# STM32WL5x_CM0P register map
File version: 1.5
CPU: CM0 r0p1, little endian, MPU, no FPU, 4 interrupt priority bits
Registers are 32-bit, read-write, reset 0x0 unless marked. A register's access mark holds for its fields unless they carry their own. Offsets are from the block's base; [hi:lo] are bit positions; {n}, {i} and the like mark numbered series.

## DMAMUX — DMA request multiplexer
Base 0x40020800
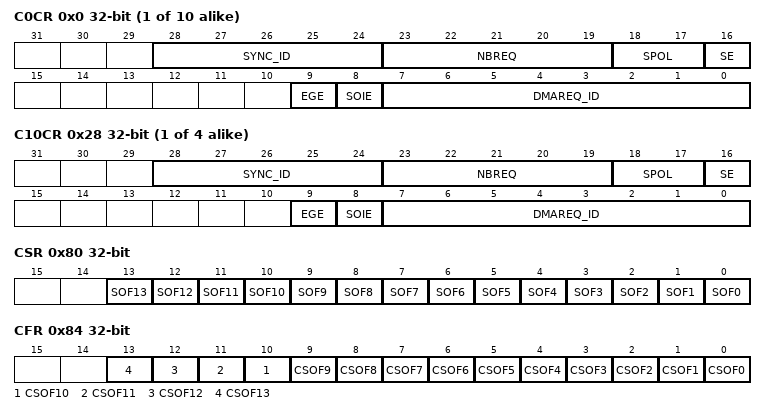
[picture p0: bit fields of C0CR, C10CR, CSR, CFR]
{0x0+4i} C{i}CR (i=0..9) — request line multiplexer channel x configuration register
  [28:24] SYNC_ID — Synchronization identification
  [23:19] NBREQ — Number of DMA requests minus 1 to forward
  [18:17] SPOL — Synchronization polarity
  [16] SE — Synchronization enable
  [9] EGE — Event generation enable
  [8] SOIE — Synchronization overrun interrupt enable
  [7:0] DMAREQ_ID — DMA request identification
{0x0+4i} C{i}CR (i=10..13)
  [28:24] SYNC_ID, [23:19] NBREQ, [18:17] SPOL, [16] SE, [9] EGE, [8] SOIE, [7:0] DMAREQ_ID
0x80 CSR ro — request line multiplexer interrupt channel status register
  [13] SOF13 — Synchronization overrun event flag
  [n] SOF{n} (n=0..12)
0x84 CFR — request line multiplexer interrupt channel clear flag register
  [n] CSOF{n} (n=0..13)
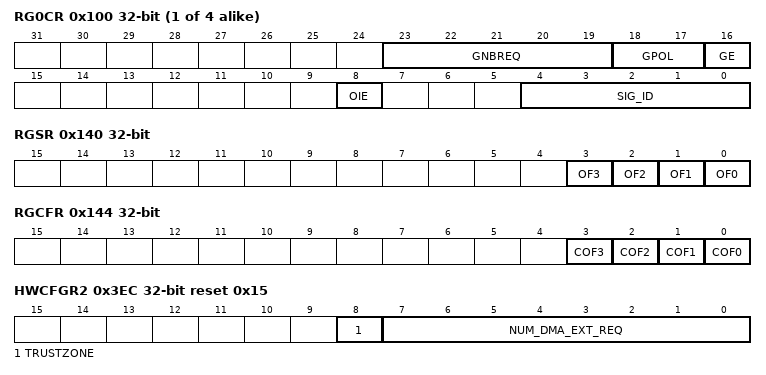
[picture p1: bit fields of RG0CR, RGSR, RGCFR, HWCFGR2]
{0x100+4i} RG{i}CR (i=0..3) — request generator channel x configuration register
  [23:19] GNBREQ — Number of DMA requests to be generated (minus 1)
  [18:17] GPOL — DMA request generator trigger polarity
  [16] GE — DMA request generator channel x enable
  [8] OIE — Trigger overrun interrupt enable
  [4:0] SIG_ID — Signal identification
0x140 RGSR ro — request generator interrupt status register
  [3] OF3 — Trigger overrun event flag
  [2] OF2
  [1] OF1
  [0] OF0
0x144 RGCFR wo — request generator interrupt clear flag register
  [3] COF3 — Clear trigger overrun event flag
  [2] COF2
  [1] COF1
  [0] COF0
0x3EC HWCFGR2 reset 0x15 — hardware configuration 2 register [non-user]
  [8] TRUSTZONE — TrustZone support
  [7:0] NUM_DMA_EXT_REQ — Number of DMA request trigger inputs
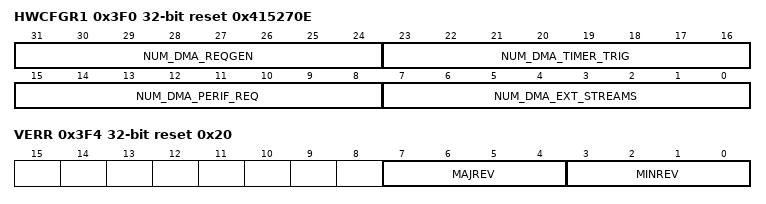
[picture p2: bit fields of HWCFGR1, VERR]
0x3F0 HWCFGR1 ro reset 0x415270E — hardware configuration 1 register [non-user]
  [31:24] NUM_DMA_REQGEN — number of DMA request generator channels
  [23:16] NUM_DMA_TIMER_TRIG — number of synchronization inputs
  [15:8] NUM_DMA_PERIF_REQ — number of DMA request lines from peripherals
  [7:0] NUM_DMA_EXT_STREAMS — number of DMA request line multiplexer (output) channels
0x3F4 VERR reset 0x20 — version register [non-user]
  [7:4] MAJREV — Major IP revision
  [3:0] MINREV — Minor IP revision
0x3F8 IPIDR ro reset 0x100011 — IP identification register [non-user]
  [31:0] ID — IP identification
0x3FC SIDR ro reset 0xA3C5DD01 — size identification register [non-user]
  [31:0] SID — Size identification

## PKA — Public key accelerator
Base 0x58002000
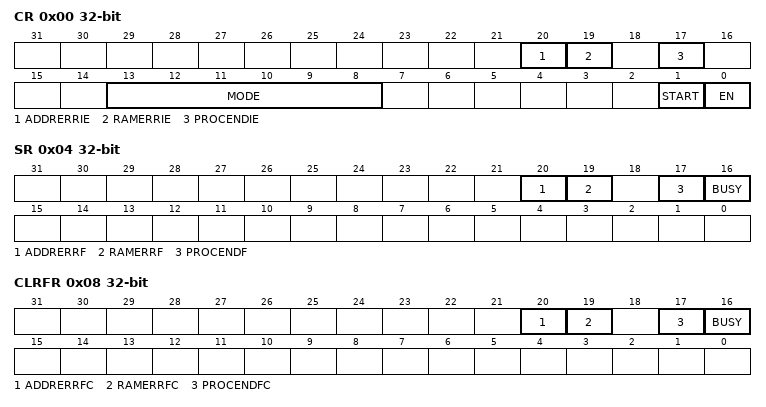
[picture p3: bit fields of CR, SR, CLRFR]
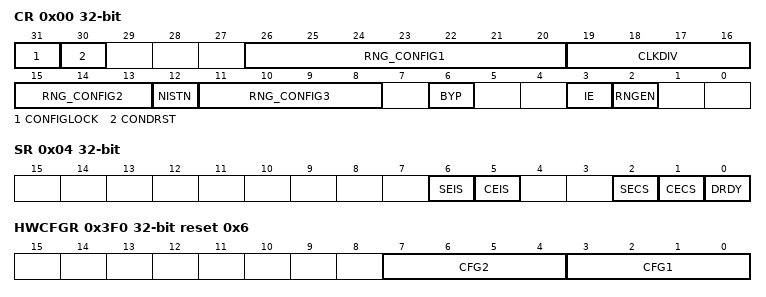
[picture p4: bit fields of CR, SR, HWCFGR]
0x00 CR — control register
  [20] ADDRERRIE — Address error interrupt enable
  [19] RAMERRIE — RAM error interrupt enable
  [17] PROCENDIE
  [13:8] MODE — PKA operation code
  [1] START — start the operation
  [0] EN — PKA enable.
0x04 SR ro — status register
  [20] ADDRERRF — Address error flag
  [19] RAMERRF — PKA RAM error flag
  [17] PROCENDF — PKA End of Operation flag
  [16] BUSY — PKA operation is in progressThis bit is set to 1 whenever START bit in the PKA_CR is set. It is automatically cleared when the computation is complete, meaning that PKA RAM can be safely accessed and a new operation can be started.
0x08 CLRFR wo — clear flag register
  [20] ADDRERRFC — Clear Address error flag
  [19] RAMERRFC — Clear PKA RAM error flag
  [17] PROCENDFC — Clear PKA End of Operation flag
  [16] BUSY — PKA operation is in progress?

## RNG — True random number generator
Base 0x58001000
0x00 CR — control register
  [31] CONFIGLOCK
  [30] CONDRST — Conditioning soft reset
  [26:20] RNG_CONFIG1
  [19:16] CLKDIV
  [15:13] RNG_CONFIG2
  [12] NISTN
  [11:8] RNG_CONFIG3
  [6] BYP — Bypass mode enable (non-user)
  [3] IE — Interrupt Enable
  [2] RNGEN — True random number generator enable
0x04 SR access per field — status register
  [6] SEIS rw — Seed error interrupt status
  [5] CEIS rw — Clock error interrupt status
  [2] SECS ro — Seed error current status
  [1] CECS ro — Clock error current status
  [0] DRDY ro — Data Ready
0x08 DR ro — data register
  [31:0] RNDATA — Random data
0x3F0 HWCFGR ro reset 0x6 — RNG hardware Configuration Register
  [7:4] CFG2, [3:0] CFG1
0x3F4 VER ro reset 0x30 — RNG Version Register
  [7:0] VER
0x3F8 ID ro reset 0x170041
0x3FC MID ro reset 0xA3C5DD01
